VERSION ""

NS_ :

BS_:

BU_:

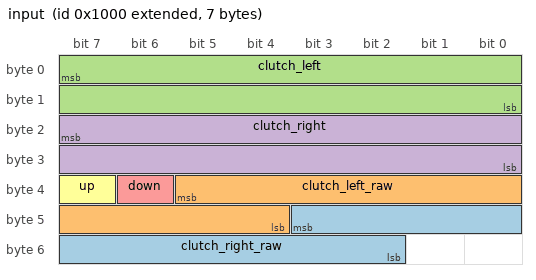
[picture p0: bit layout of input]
BO_ 2147487744 input: 7 Vector__XXX
 SG_ clutch_right_raw : 43|10@0+ (1,0) [0|0] "" Vector__XXX
 SG_ clutch_left_raw : 37|10@0+ (1,0) [0|0] "" Vector__XXX
 SG_ clutch_left : 7|16@0+ (0.01,0) [0|100] "%" Vector__XXX
 SG_ clutch_right : 23|16@0+ (0.01,0) [0|100] "%" Vector__XXX
 SG_ down : 38|1@0+ (1,0) [0|0] "boolean" Vector__XXX
 SG_ up : 39|1@0+ (1,0) [0|0] "boolean" Vector__XXX

BA_DEF_  "BusType" STRING ;
BA_DEF_ BO_  "GenMsgCycleTime" INT 0 0;
BA_DEF_DEF_  "BusType" "CAN";
BA_DEF_DEF_  "GenMsgCycleTime" 0;
BA_ "GenMsgCycleTime" BO_ 2147487744 10;
